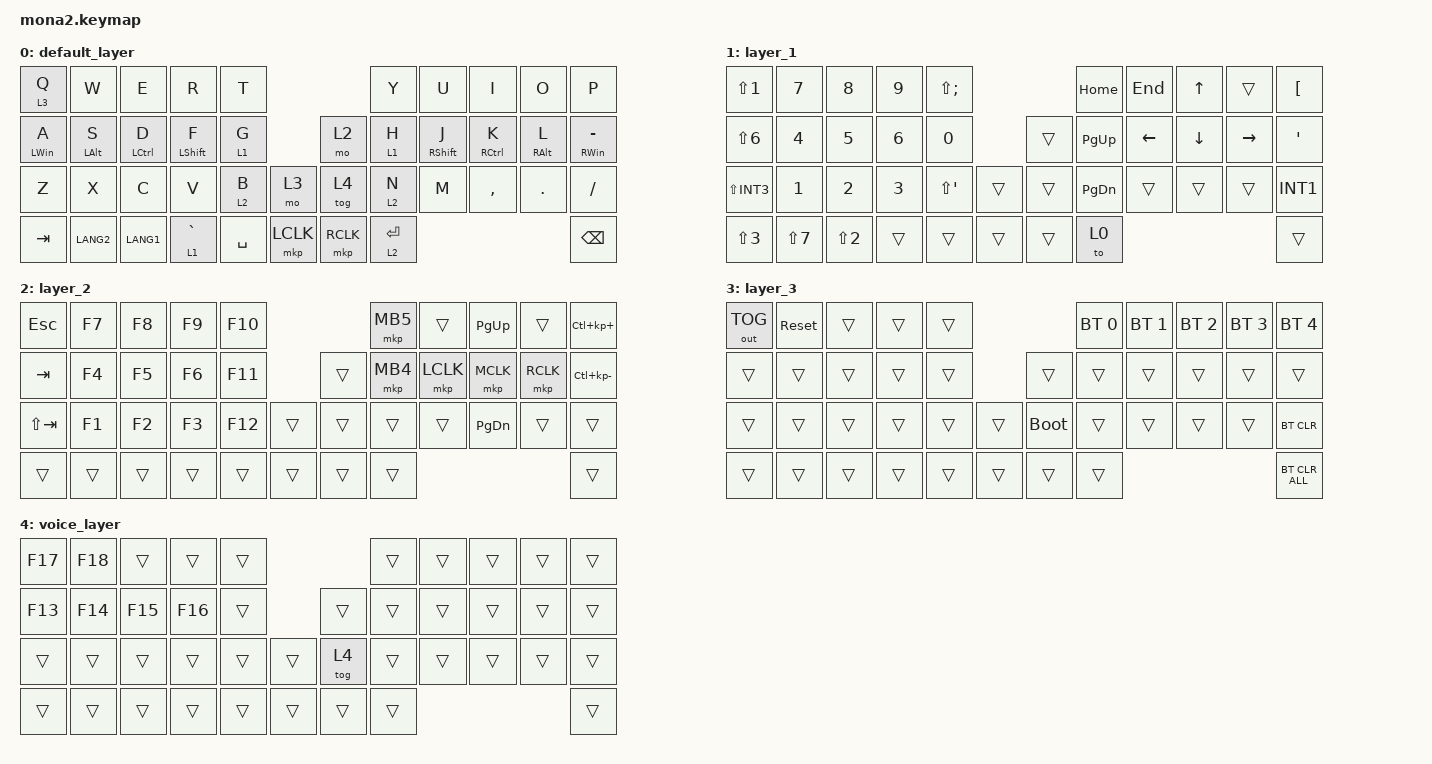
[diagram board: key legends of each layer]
#include <input/processors.dtsi>
#include <dt-bindings/zmk/input_transform.h>
#include <zephyr/dt-bindings/input/input-event-codes.h>
#include <behaviors.dtsi>
#include <dt-bindings/zmk/bt.h>
#include <dt-bindings/zmk/keys.h>
#include <dt-bindings/zmk/pointing.h>
#include <dt-bindings/zmk/outputs.h>

#define ZMK_POINTING_DEFAULT_SCRL_VAL 100

/*
 * ==========================================================================
 * moNa2 keymap  (keyball39 QMK -> ZMK 移植版 / JIS配列)
 *
 * 物理キー位置番号 (combos の key-positions で使用):
 *   0  1  2  3  4            5  6  7  8  9
 *   10 11 12 13 14   15      16 17 18 19 20
 *   21 22 23 24 25   26  27  28 29 30 31 32
 *   33 34 35 36 37   38  39  40                41
 *
 *   ※ 15 / 26 / 27 が keyball39 には無い「増設キー(+3)」。
 *   ※ 34 / 35 は keyball39 では base が空きの親指キー(L1で ' ")。
 *
 *   ★ 今回の追加（既存は保持）:
 *      (1) Python/C#/C++ 向け記号コンボ（JIS-HID準拠）
 *      (2) Home Row Mods の bilateral 化（hml/hmr/mt_pinky_l/r）
 *      (4) 音声レイヤー(layer 4): F13〜F18 を Talon/Wispr Flow 側に割当
 * ==========================================================================
 */

/* ★(2) bilateral 判定用の左右キー群（反対の手のキーが押された時だけ hold） */
#define KEYS_L  0 1 2 3 4    10 11 12 13 14   21 22 23 24 25   33 34 35 36 37
#define KEYS_R  5 6 7 8 9    16 17 18 19 20   28 29 30 31 32   38 39 40 41
#define KEYS_C  15 26 27

/* 通常の mod-tap / layer-tap の共通設定
 * require-prior-idle-ms = QMK の Flow Tap 相当 (直前打鍵から一定時間内はタップ確定)。 */
&mt {
    flavor = "balanced";
    tapping-term-ms = <250>;
    quick-tap-ms = <0>;
    require-prior-idle-ms = <180>;
};

&lt {
    flavor = "balanced";
    tapping-term-ms = <250>;
    quick-tap-ms = <300>;
    require-prior-idle-ms = <180>;
};

/ {
    behaviors {
        /* 旧 mt_pinky (bilateral 非対応)。下の _l/_r に置換済みだが、戻せるよう残置。 */
        mt_pinky: mod_tap_pinky {
            compatible = "zmk,behavior-hold-tap";
            #binding-cells = <2>;
            flavor = "balanced";
            tapping-term-ms = <320>;
            quick-tap-ms = <0>;
            require-prior-idle-ms = <180>;
            bindings = <&kp>, <&kp>;
        };

        /* ★(2) Home Row Mods: 左手用（反対=右手+中央キーでのみ hold 成立） */
        hml: home_row_mod_left {
            compatible = "zmk,behavior-hold-tap";
            #binding-cells = <2>;
            flavor = "balanced";
            tapping-term-ms = <250>;
            quick-tap-ms = <0>;
            require-prior-idle-ms = <180>;
            hold-trigger-key-positions = <KEYS_R KEYS_C>;
            hold-trigger-on-release;
            bindings = <&kp>, <&kp>;
        };
        /* ★(2) Home Row Mods: 右手用 */
        hmr: home_row_mod_right {
            compatible = "zmk,behavior-hold-tap";
            #binding-cells = <2>;
            flavor = "balanced";
            tapping-term-ms = <250>;
            quick-tap-ms = <0>;
            require-prior-idle-ms = <180>;
            hold-trigger-key-positions = <KEYS_L KEYS_C>;
            hold-trigger-on-release;
            bindings = <&kp>, <&kp>;
        };
        /* ★(2) 小指 (A / -) 専用: 300ms + bilateral */
        mt_pinky_l: mod_tap_pinky_left {
            compatible = "zmk,behavior-hold-tap";
            #binding-cells = <2>;
            flavor = "balanced";
            tapping-term-ms = <320>;
            quick-tap-ms = <0>;
            require-prior-idle-ms = <180>;
            hold-trigger-key-positions = <KEYS_R KEYS_C>;
            hold-trigger-on-release;
            bindings = <&kp>, <&kp>;
        };
        mt_pinky_r: mod_tap_pinky_right {
            compatible = "zmk,behavior-hold-tap";
            #binding-cells = <2>;
            flavor = "balanced";
            tapping-term-ms = <320>;
            quick-tap-ms = <0>;
            require-prior-idle-ms = <180>;
            hold-trigger-key-positions = <KEYS_L KEYS_C>;
            hold-trigger-on-release;
            bindings = <&kp>, <&kp>;
        };

        /* トラックボール用センサ回転 */
        scroll_up_down: scroll_up_down {
            compatible = "zmk,behavior-sensor-rotate";
            #sensor-binding-cells = <0>;
            bindings = <&msc SCRL_UP>, <&msc SCRL_DOWN>;
            tap-ms = <20>;
        };
        scroll_right_left: scroll_right_left {
            compatible = "zmk,behavior-sensor-rotate";
            #sensor-binding-cells = <0>;
            bindings = <&msc SCRL_LEFT>, <&msc SCRL_RIGHT>;
            tap-ms = <20>;
        };
    };

    macros {
        /* ===== 既存マクロ（保持・変更なし） ===== */
        ArrowL: ArrowL {            /* "->"  : KC_MINUS, S(KC_DOT) */
            compatible = "zmk,behavior-macro";
            #binding-cells = <0>;
            bindings = <&kp MINUS &kp LS(DOT)>;
        };
        ArrowR: ArrowR {            /* "<-"  : S(KC_COMMA), KC_MINUS */
            compatible = "zmk,behavior-macro";
            #binding-cells = <0>;
            bindings = <&kp LS(COMMA) &kp MINUS>;
        };
        ParentHeses: ParentHeses {  /* "()<-" : S(KC_8) S(KC_9) KC_LEFT */
            compatible = "zmk,behavior-macro";
            #binding-cells = <0>;
            bindings = <&kp LS(N8) &kp LS(N9) &kp LEFT>;
        };
        Brackets: Brackets {        /* "[]<-" : KC_RBRC KC_BSLS KC_LEFT */
            compatible = "zmk,behavior-macro";
            #binding-cells = <0>;
            bindings = <&kp RBKT &kp BSLH &kp LEFT>;
        };
        Curlybrackets: Curlybrackets {  /* "{}<-" : S(KC_RBRC) S(KC_BSLS) KC_LEFT */
            compatible = "zmk,behavior-macro";
            #binding-cells = <0>;
            bindings = <&kp LS(RBKT) &kp LS(BSLH) &kp LEFT>;
        };

        /* ===== ★(1) 追加: コーディング記号マクロ（JIS-HID準拠） =====
         * JIS対応の根拠（既存マクロと同じ流儀でHIDを直接送出）:
         *   =  ->  LS(MINUS)     >  -> LS(DOT)     <  -> LS(COMMA)
         *   !  ->  LS(N1)        &  -> LS(N6)      |  -> LS(INT3)
         *   :  ->  SQT           *  -> LS(SQT)     ?  -> LS(SLASH)
         */
        m_eq2:   m_eq2   { compatible="zmk,behavior-macro"; #binding-cells=<0>;
            bindings = <&kp LS(MINUS) &kp LS(MINUS)>; };          /* ==  */
        m_neq:   m_neq   { compatible="zmk,behavior-macro"; #binding-cells=<0>;
            bindings = <&kp LS(N1) &kp LS(MINUS)>; };             /* !=  */
        m_geq:   m_geq   { compatible="zmk,behavior-macro"; #binding-cells=<0>;
            bindings = <&kp LS(DOT) &kp LS(MINUS)>; };            /* >=  */
        m_leq:   m_leq   { compatible="zmk,behavior-macro"; #binding-cells=<0>;
            bindings = <&kp LS(COMMA) &kp LS(MINUS)>; };          /* <=  */
        m_fatarrow: m_fatarrow { compatible="zmk,behavior-macro"; #binding-cells=<0>;
            bindings = <&kp LS(MINUS) &kp LS(DOT)>; };            /* =>  (C# lambda) */
        m_and2:  m_and2  { compatible="zmk,behavior-macro"; #binding-cells=<0>;
            bindings = <&kp LS(N6) &kp LS(N6)>; };                /* &&  */
        m_or2:   m_or2   { compatible="zmk,behavior-macro"; #binding-cells=<0>;
            bindings = <&kp LS(INT3) &kp LS(INT3)>; };            /* ||  */
        m_scope: m_scope { compatible="zmk,behavior-macro"; #binding-cells=<0>;
            bindings = <&kp SQT &kp SQT>; };                      /* ::  (C++ scope) */

        /* --- ★(1) 追加(任意): デフォルトでは下のコンボをコメントアウトで無効。
         *         使うときだけ combos 側の対応行を有効化。 --- */
        m_walrus: m_walrus { compatible="zmk,behavior-macro"; #binding-cells=<0>;
            bindings = <&kp SQT &kp LS(MINUS)>; };                /* :=  (Python walrus) */
        m_pow:   m_pow   { compatible="zmk,behavior-macro"; #binding-cells=<0>;
            bindings = <&kp LS(SQT) &kp LS(SQT)>; };              /* **  (Python) */
        m_shl:   m_shl   { compatible="zmk,behavior-macro"; #binding-cells=<0>;
            bindings = <&kp LS(COMMA) &kp LS(COMMA)>; };          /* <<  (C++ stream) */
        m_shr:   m_shr   { compatible="zmk,behavior-macro"; #binding-cells=<0>;
            bindings = <&kp LS(DOT) &kp LS(DOT)>; };              /* >>  (C++ stream) */
        m_angle: m_angle { compatible="zmk,behavior-macro"; #binding-cells=<0>;
            bindings = <&kp LS(COMMA) &kp LS(DOT) &kp LEFT>; };   /* <>  generics/template, カーソル内側 */
        m_coalesce: m_coalesce { compatible="zmk,behavior-macro"; #binding-cells=<0>;
            bindings = <&kp LS(SLASH) &kp LS(SLASH)>; };          /* ??  (C# null合体) */
        m_safecall: m_safecall { compatible="zmk,behavior-macro"; #binding-cells=<0>;
            bindings = <&kp LS(SLASH) &kp DOT>; };                /* ?.  (C# null条件) */
    };

    combos {
        compatible = "zmk,combos";

        /* ===== 既存コンボ（保持・変更なし） ===== */
        combo_tab     { key-positions = <3 4>;    bindings = <&kp TAB>;       timeout-ms = <40>; layers = <0>; }; /* R+T */
        combo_home    { key-positions = <5 6>;    bindings = <&kp HOME>;      timeout-ms = <40>; layers = <0>; }; /* Y+U */
        combo_end     { key-positions = <28 29>;  bindings = <&kp END>;       timeout-ms = <40>; layers = <0>; }; /* N+M */
        combo_semi    { key-positions = <19 20>;  bindings = <&kp SEMICOLON>; timeout-ms = <40>; layers = <0>; }; /* L+- -> ; */
        combo_colon   { key-positions = <18 19>;  bindings = <&kp SQT>;       timeout-ms = <40>; layers = <0>; }; /* K+L -> : (JIS) */
        combo_delword { key-positions = <8 9>;    bindings = <&kp LC(BSPC)>;  timeout-ms = <40>; layers = <0>; }; /* O+P */
        combo_del     { key-positions = <31 32>;  bindings = <&kp DEL>;       timeout-ms = <40>; layers = <0>; }; /* .+/ */
        combo_caps    { key-positions = <1 2 3>;  bindings = <&caps_word>;    timeout-ms = <40>; layers = <0>; }; /* W+E+R */
        combo_paren   { key-positions = <11 12>;  bindings = <&ParentHeses>;  timeout-ms = <50>; layers = <0>; }; /* S+D -> () */
        combo_brkt    { key-positions = <12 13>;  bindings = <&Brackets>;     timeout-ms = <50>; layers = <0>; }; /* D+F -> [] */
        combo_cbrkt   { key-positions = <11 13>;  bindings = <&Curlybrackets>;timeout-ms = <50>; layers = <0>; }; /* S+F -> {} */
        combo_arrowL  { key-positions = <11 12>;  bindings = <&ArrowL>; timeout-ms = <50>; layers = <1>; };       /* S+D -> "->" */
        combo_arrowR  { key-positions = <12 13>;  bindings = <&ArrowR>; timeout-ms = <50>; layers = <1>; };       /* D+F -> "<-" */

        /* ===== ★(1) 追加コンボ（core: 優先 Python>C#>C++ で頻出のもの） =====
         * 配置方針: 既存と衝突しない位置を選択。右上=比較系 / 左下=論理・C++系。
         * 誤爆するペアがあれば key-positions を空き番号に移すか timeout を下げる。 */
        combo_eq2     { key-positions = <6 7>;    bindings = <&m_eq2>;      timeout-ms = <40>; layers = <0>; }; /* U+I -> == */
        combo_neq     { key-positions = <7 8>;    bindings = <&m_neq>;      timeout-ms = <40>; layers = <0>; }; /* I+O -> != */
        combo_geq     { key-positions = <16 17>;  bindings = <&m_geq>;      timeout-ms = <40>; layers = <0>; }; /* H+J -> >= */
        combo_leq     { key-positions = <17 18>;  bindings = <&m_leq>;      timeout-ms = <40>; layers = <0>; }; /* J+K -> <= */
        combo_fatarw  { key-positions = <21 22>;  bindings = <&m_fatarrow>; timeout-ms = <40>; layers = <0>; }; /* Z+X -> => */
        combo_and2    { key-positions = <22 23>;  bindings = <&m_and2>;     timeout-ms = <40>; layers = <0>; }; /* X+C -> && */
        combo_or2     { key-positions = <23 24>;  bindings = <&m_or2>;      timeout-ms = <40>; layers = <0>; }; /* C+V -> || */
        combo_scope   { key-positions = <24 25>;  bindings = <&m_scope>;    timeout-ms = <40>; layers = <0>; }; /* V+B -> :: */

        /* ===== ★(1) 追加コンボ（extended: 必要になったら有効化） =====
         * まずは core を体に入れてから。最初に全部入れると誤爆と記憶負荷で挫折しがち。 */
        // combo_walrus  { key-positions = <6 8>;    bindings = <&m_walrus>;   timeout-ms = <40>; layers = <0>; }; /* U+O -> :=  Python */
        // combo_pow     { key-positions = <0 1>;    bindings = <&m_pow>;      timeout-ms = <40>; layers = <0>; }; /* Q+W -> **  Python */
        // combo_shl     { key-positions = <29 30>;  bindings = <&m_shl>;      timeout-ms = <40>; layers = <0>; }; /* M+, -> <<  C++ */
        // combo_shr     { key-positions = <30 31>;  bindings = <&m_shr>;      timeout-ms = <40>; layers = <0>; }; /* ,+. -> >>  C++ */
        // combo_angle   { key-positions = <13 14>;  bindings = <&m_angle>;    timeout-ms = <40>; layers = <0>; }; /* F+G -> <>  generics */
        // combo_coalesce{ key-positions = <17 19>;  bindings = <&m_coalesce>; timeout-ms = <40>; layers = <0>; }; /* J+L -> ??  C# */
        // combo_safecall{ key-positions = <18 20>;  bindings = <&m_safecall>; timeout-ms = <40>; layers = <0>; }; /* K+- -> ?.  C# */
    };

    keymap {
        compatible = "zmk,keymap";

        /* ====================== Layer 0 (Base) ======================
         * ★(2) 変更点: home row を hml/hmr/mt_pinky_l/r に置換（bilateral化）。
         * ★(4) 変更点: 中央キー pos27 (旧 &trans) を &tog 4 に（音声レイヤー入/切）。
         * それ以外は変更なし。 */
        default_layer {
            bindings = <
&lt 3 Q              &kp W          &kp E         &kp R             &kp T                                      &kp Y    &kp U              &kp I         &kp O           &kp P
&mt_pinky_l LWIN A   &hml LALT S    &hml LCTRL D  &hml LSHFT F      &lt 1 G                     &mo 2          &lt 1 H  &hmr RSHFT J       &hmr RCTRL K  &hmr RALT L     &mt_pinky_r RWIN MINUS
&kp Z                &kp X          &kp C         &kp V             &lt 2 B    &mo 3            &tog 4         &lt 2 N  &kp M              &kp COMMA     &kp DOT         &kp SLASH
&kp TAB              &kp LANG2      &kp LANG1     &lt 1 GRAVE       &kp SPACE  &mkp LCLK        &mkp RCLK      &lt 2 ENTER                                              &kp BACKSPACE
            >;
            sensor-bindings = <&scroll_up_down>;
        };

        /* ====================== Layer 1 (num / nav / sym) ====================== */
        layer_1 {
            bindings = <
&kp LS(N1)  &kp N7      &kp N8      &kp N9      &kp LS(SEMI)                          &kp HOME    &kp END   &kp UP    &trans     &kp LBKT
&kp LS(N6)  &kp N4      &kp N5      &kp N6      &kp N0                      &trans     &kp PG_UP   &kp LEFT  &kp DOWN  &kp RIGHT  &kp SQT
&kp LS(INT3)&kp N1      &kp N2      &kp N3      &kp LS(SQT)  &trans         &trans     &kp PG_DN   &trans    &trans     &trans    &kp INT1
&kp LS(N3)  &kp LS(N7)  &kp LS(N2)  &trans      &trans       &trans         &trans     &to 0                                       &trans
            >;
            sensor-bindings = <&scroll_right_left>;
        };

        /* ====================== Layer 2 (F-keys / mouse) ====================== */
        layer_2 {
            bindings = <
&kp ESC     &kp F7  &kp F8  &kp F9  &kp F10                       &mkp MB5  &trans     &kp PG_UP  &trans    &kp LC(KP_PLUS)
&kp TAB     &kp F4  &kp F5  &kp F6  &kp F11             &trans    &mkp MB4  &mkp LCLK  &mkp MCLK  &mkp RCLK &kp LC(KP_MINUS)
&kp LS(TAB) &kp F1  &kp F2  &kp F3  &kp F12  &trans     &trans    &trans    &trans     &kp PG_DN  &trans    &trans
&trans      &trans  &trans  &trans  &trans   &trans     &trans    &trans                                    &trans
            >;
            sensor-bindings = <&scroll_up_down>;
        };

        /* ====================== Layer 3 (BT / system) ====================== */
        layer_3 {
            bindings = <
&out OUT_TOG  &sys_reset  &trans  &trans  &trans                        &bt BT_SEL 0  &bt BT_SEL 1  &bt BT_SEL 2  &bt BT_SEL 3  &bt BT_SEL 4
&trans        &trans      &trans  &trans  &trans          &trans        &trans        &trans        &trans        &trans        &trans
&trans        &trans      &trans  &trans  &trans  &trans  &bootloader   &trans        &trans        &trans        &trans        &bt BT_CLR
&trans        &trans      &trans  &trans  &trans  &trans  &trans        &trans                                                  &bt BT_CLR_ALL
            >;
            sensor-bindings = <&scroll_up_down>;
        };

        /* ====================== ★(4) Layer 4 (Voice) ======================
         * F13〜F18 を「音声操作専用ホットキー」として送出（標準アプリ未使用＝衝突なし）。
         * Talon / Wispr Flow 側で割り当て:
         *   F13 = Talon sleep/wake     F14 = push-to-talk 口述(このキーを長押し)
         *   F15 = Wispr Flow トグル     F16 = 直前の音声入力を取消
         *   F17 = AI プロンプト入力     F18 = 予備
         * 入/切: base の中央キー pos27 (&tog 4) をタップ。layer内でも pos27 で抜ける。 */
        voice_layer {
            bindings = <
&kp F17  &kp F18  &trans  &trans  &trans                       &trans  &trans  &trans  &trans  &trans
&kp F13  &kp F14  &kp F15 &kp F16 &trans                &trans  &trans  &trans  &trans  &trans  &trans
&trans   &trans   &trans  &trans  &trans   &trans       &tog 4  &trans  &trans  &trans  &trans  &trans
&trans   &trans   &trans  &trans  &trans   &trans       &trans  &trans                          &trans
            >;
            sensor-bindings = <&scroll_up_down>;
        };
    };
};
